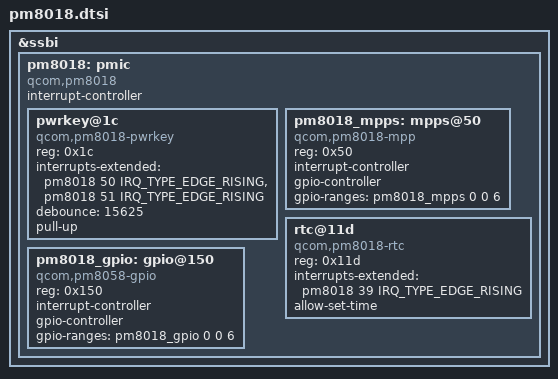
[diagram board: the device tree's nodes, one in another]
// SPDX-License-Identifier: GPL-2.0+ OR MIT
/*
 * Device Tree Source for Qualcomm PM8018
 *
 * Copyright (C) 2016 BayLibre, SAS.
 * Author : Neil Armstrong <narmstrong@baylibre.com>
 */

&ssbi {
	pm8018: pmic {
		compatible = "qcom,pm8018", "qcom,pm8921";
		#interrupt-cells = <2>;
		interrupt-controller;
		#address-cells = <1>;
		#size-cells = <0>;

		pwrkey@1c {
			compatible = "qcom,pm8018-pwrkey",
				     "qcom,pm8921-pwrkey";
			reg = <0x1c>;
			interrupts-extended = <&pm8018 50 IRQ_TYPE_EDGE_RISING>,
					      <&pm8018 51 IRQ_TYPE_EDGE_RISING>;
			debounce = <15625>;
			pull-up;
		};

		pm8018_mpps: mpps@50 {
			compatible = "qcom,pm8018-mpp", "qcom,ssbi-mpp";
			reg = <0x50>;
			interrupt-controller;
			#interrupt-cells = <2>;
			gpio-controller;
			#gpio-cells = <2>;
			gpio-ranges = <&pm8018_mpps 0 0 6>;
		};

		rtc@11d {
			compatible = "qcom,pm8018-rtc", "qcom,pm8921-rtc";
			reg = <0x11d>;
			interrupts-extended = <&pm8018 39 IRQ_TYPE_EDGE_RISING>;
			allow-set-time;
		};

		pm8018_gpio: gpio@150 {
			compatible = "qcom,pm8058-gpio",
				     "qcom,ssbi-gpio";
			reg = <0x150>;
			interrupt-controller;
			#interrupt-cells = <2>;
			gpio-controller;
			gpio-ranges = <&pm8018_gpio 0 0 6>;
			#gpio-cells = <2>;
		};
	};
};
